# STM32F410Rx register map
File version: 1.0
Registers are 32-bit, read-write, reset 0x0 unless marked. A register's access mark holds for its fields unless they carry their own. Offsets are from the block's base; [hi:lo] are bit positions; {n}, {i} and the like mark numbered series; 'fields as' and 'values as' point back to an identical list.

## RCC — Reset and Clock Control
Base 0x40023800
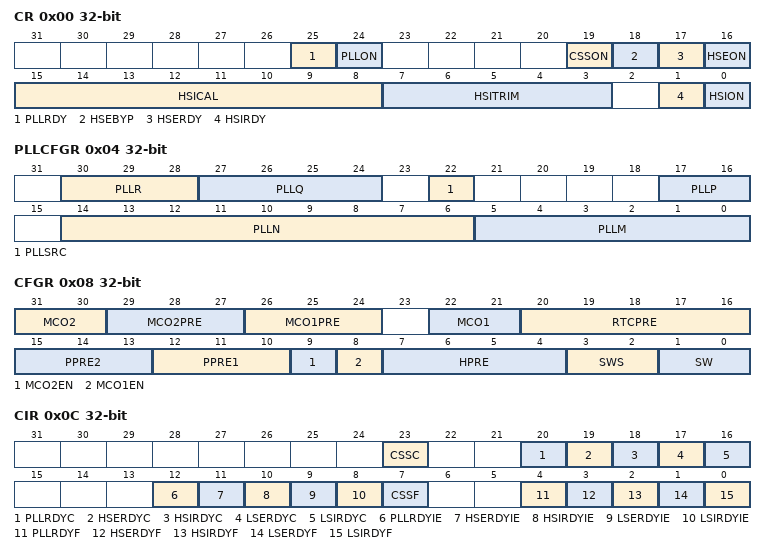
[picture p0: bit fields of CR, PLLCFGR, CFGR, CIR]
0x00 CR — RCC clock control register
  [25] PLLRDY, [24] PLLON, [19] CSSON, [18] HSEBYP, [17] HSERDY, [16] HSEON, [15:8] HSICAL, [7:3] HSITRIM, [1] HSIRDY, [0] HSION
0x04 PLLCFGR — RCC PLL configuration register
  [30:28] PLLR
    {v}=DIV_{v} (Main PLL division factor for PLLCLK (system clock) by {v}) (v=2..7)
  [27:24] PLLQ
    {v}=DIV_{v} (Main PLL division factor for PLLQ output by {v}) (v=2..15)
  [22] PLLSRC
    0=HSI (HSI16 clock selected as PLL entry clock source); 1=HSE (HSE clock selected as PLL entry clock source)
  [17:16] PLLP
    0=DIV_2 (Main PLL division factor for PLLP output by 2); 1=DIV_4 (Main PLL division factor for PLLP output by 4); 2=DIV_6 (Main PLL division factor for PLLP output by 6); 3=DIV_8 (Main PLL division factor for PLLP output by 8)
  [14:6] PLLN
  [5:0] PLLM
    {v}=DIV_{v} (PLL, PLLI2S and PLLSAI division factor by {v}) (v=2..63)
0x08 CFGR — RCC clock configuration register
  [31:30] MCO2
  [29:27] MCO2PRE
  [26:24] MCO1PRE
  [22:21] MCO1
  [20:16] RTCPRE
    0=NOCLOCK (HSE not divided); {v}=HSE_DIV_{v} (HSE clock divided by {v}) (v=2..31)
  [15:13] PPRE2 — PRE2[2:0] bits (APB2 prescaler)
    0=DIV_1 (HCLK not divided); 4=DIV_2 (HCLK divided by 2); 5=DIV_4 (HCLK divided by 4); 6=DIV_8 (HCLK divided by 8); 7=DIV_16 (HCLK divided by 16)
  [12:10] PPRE1 — PRE1[2:0] bits (APB1 prescaler)
    values as PPRE2
  [9] MCO2EN — MCO2EN bit
  [8] MCO1EN — MCO1EN bit
  [7:4] HPRE — HPRE[3:0] bits (AHB prescaler)
    0=DIV_1 (SYSCLK not divided); 8=DIV_2 (SYSCLK divided by 2); 9=DIV_4 (SYSCLK divided by 4); 10=DIV_8 (SYSCLK divided by 8); 11=DIV_16 (SYSCLK divided by 16); 12=DIV_64 (SYSCLK divided by 64); 13=DIV_128 (SYSCLK divided by 128); 14=DIV_256 (SYSCLK divided by 256); 15=DIV_512 (SYSCLK divided by 512)
  [3:2] SWS — SWS[1:0] bits (System Clock Switch Status)
    0=HSI (HSI used as system clock); 1=HSE (HSE used as system clock); 2=PLL (PLL used as system clock)
  [1:0] SW — SW[1:0] bits (System clock Switch)
    0=HSI (HSI selection as system clock); 1=HSE (HSE selection as system clock); 2=PLL (PLL selection as system clock)
0x0C CIR — RCC clock interrupt register
  [23] CSSC, [20] PLLRDYC, [19] HSERDYC, [18] HSIRDYC, [17] LSERDYC, [16] LSIRDYC, [12] PLLRDYIE, [11] HSERDYIE, [10] HSIRDYIE, [9] LSERDYIE, [8] LSIRDYIE, [7] CSSF, [4] PLLRDYF, [3] HSERDYF, [2] HSIRDYF, [1] LSERDYF, [0] LSIRDYF
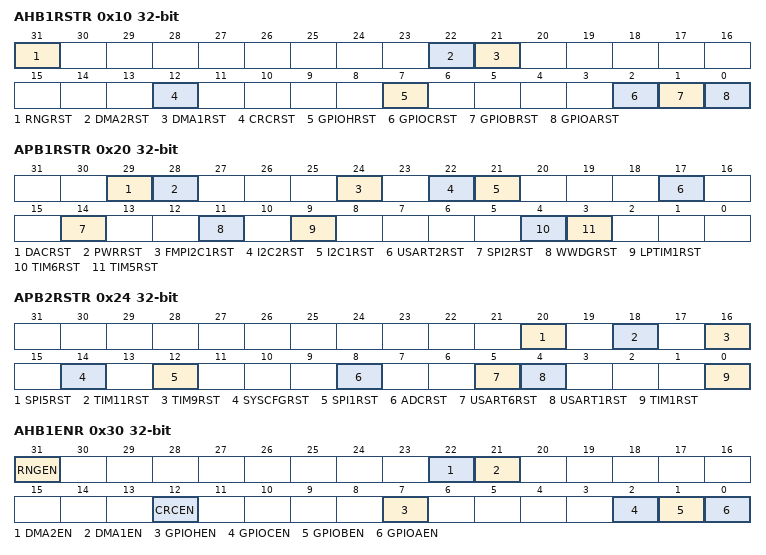
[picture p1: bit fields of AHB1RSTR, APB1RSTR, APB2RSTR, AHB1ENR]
0x10 AHB1RSTR — RCC AHB1 peripheral reset register
  [31] RNGRST, [22] DMA2RST, [21] DMA1RST, [12] CRCRST, [7] GPIOHRST, [2] GPIOCRST, [1] GPIOBRST, [0] GPIOARST
0x20 APB1RSTR — RCC APB1 peripheral reset register
  [29] DACRST, [28] PWRRST, [24] FMPI2C1RST, [22] I2C2RST, [21] I2C1RST, [17] USART2RST, [14] SPI2RST, [11] WWDGRST, [9] LPTIM1RST, [4] TIM6RST, [3] TIM5RST
0x24 APB2RSTR — RCC APB2 peripheral reset register
  [20] SPI5RST, [18] TIM11RST, [16] TIM9RST, [14] SYSCFGRST, [12] SPI1RST, [8] ADCRST, [5] USART6RST, [4] USART1RST, [0] TIM1RST
0x30 AHB1ENR — RCC AHB1 peripheral clock register
  [31] RNGEN, [22] DMA2EN, [21] DMA1EN, [12] CRCEN, [7] GPIOHEN, [2] GPIOCEN, [1] GPIOBEN, [0] GPIOAEN
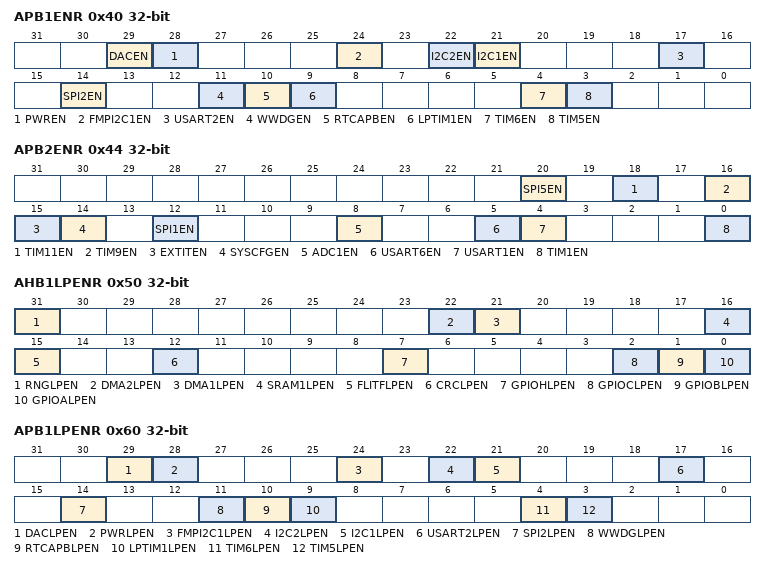
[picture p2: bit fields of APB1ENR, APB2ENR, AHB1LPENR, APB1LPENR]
0x40 APB1ENR — RCC APB1 peripheral clock enable register
  [29] DACEN, [28] PWREN, [24] FMPI2C1EN, [22] I2C2EN, [21] I2C1EN, [17] USART2EN, [14] SPI2EN, [11] WWDGEN, [10] RTCAPBEN, [9] LPTIM1EN, [4] TIM6EN, [3] TIM5EN
0x44 APB2ENR — RCC APB2 peripheral clock enable register
  [20] SPI5EN, [18] TIM11EN, [16] TIM9EN, [15] EXTITEN, [14] SYSCFGEN, [12] SPI1EN, [8] ADC1EN, [5] USART6EN, [4] USART1EN, [0] TIM1EN
0x50 AHB1LPENR — RCC AHB1 peripheral clock enable in low power mode register
  [31] RNGLPEN, [22] DMA2LPEN, [21] DMA1LPEN, [16] SRAM1LPEN, [15] FLITFLPEN, [12] CRCLPEN, [7] GPIOHLPEN, [2] GPIOCLPEN, [1] GPIOBLPEN, [0] GPIOALPEN
0x60 APB1LPENR — RCC APB1 peripheral clock enable in low power mode register
  [29] DACLPEN, [28] PWRLPEN, [24] FMPI2C1LPEN, [22] I2C2LPEN, [21] I2C1LPEN, [17] USART2LPEN, [14] SPI2LPEN, [11] WWDGLPEN, [10] RTCAPBLPEN, [9] LPTIM1LPEN, [4] TIM6LPEN, [3] TIM5LPEN
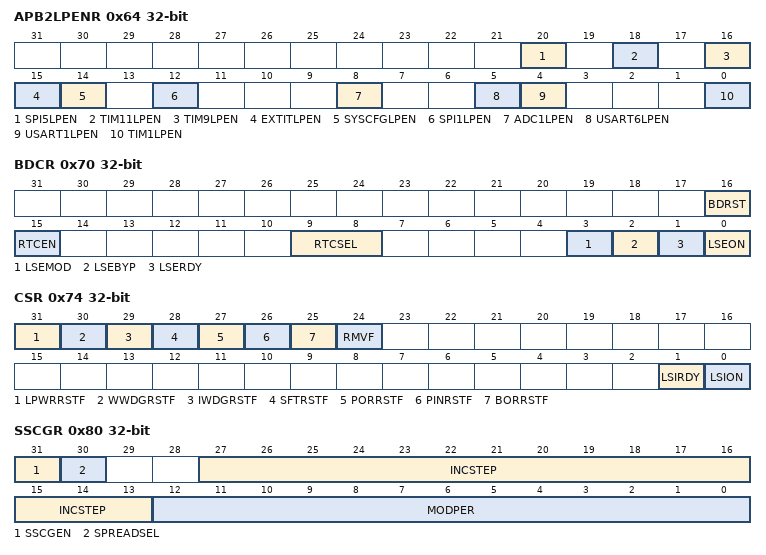
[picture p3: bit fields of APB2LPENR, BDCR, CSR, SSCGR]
0x64 APB2LPENR — RCC APB2 peripheral clock enable in low power mode register
  [20] SPI5LPEN, [18] TIM11LPEN, [16] TIM9LPEN, [15] EXTITLPEN, [14] SYSCFGLPEN, [12] SPI1LPEN, [8] ADC1LPEN, [5] USART6LPEN, [4] USART1LPEN, [0] TIM1LPEN
0x70 BDCR — RCC Backup domain control register
  [16] BDRST
  [15] RTCEN
  [9:8] RTCSEL
    0=NONE (No clock used as RTC clock); 1=LSE (LSE oscillator clock used as RTC clock); 2=LSI (LSI oscillator clock used as RTC clock); 3=HSE (HSE oscillator clock divided by HSE prescaler used as RTC clock)
  [3] LSEMOD
  [2] LSEBYP
  [1] LSERDY
  [0] LSEON
0x74 CSR — RCC clock control & status register
  [31] LPWRRSTF, [30] WWDGRSTF, [29] IWDGRSTF, [28] SFTRSTF, [27] PORRSTF, [26] PINRSTF, [25] BORRSTF, [24] RMVF, [1] LSIRDY, [0] LSION
0x80 SSCGR — RCC spread spectrum clock generation register
  [31] SSCGEN
  [30] SPREADSEL
    0=CENTER (PLL center spread spectrum selection); 1=DOWN (PLL down spread spectrum selection)
  [27:13] INCSTEP
  [12:0] MODPER
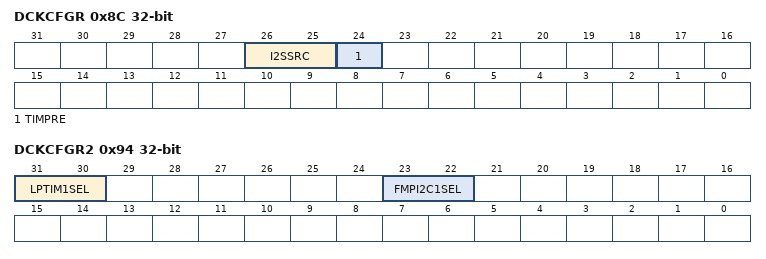
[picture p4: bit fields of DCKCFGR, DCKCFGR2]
0x8C DCKCFGR — RCC DCKCFGR configuration register
  [26:25] I2SSRC
  [24] TIMPRE
    0=TWICE (Timers clock to twice PCLK); 1=FOUR_TIMES (Timers clock to four time PCLK)
0x90 CKGATENR — RCC Clocks Gated ENable Register
0x94 DCKCFGR2 — RCC Dedicated Clocks configuration register 2
  [31:30] LPTIM1SEL
    0=PCLK1 (PCLK1 clock used as LPTIM1 clock); 1=HSI (LSI oscillator clock used as LPTIM1 clock); 2=LSI (HSI oscillator clock used as LPTIM1 clock); 3=LSE (LSE oscillator clock used as LPTIM1 clock)
  [23:22] FMPI2C1SEL
    0=PCLK1 (PCLK1 clock used as FMPI2C1 clock source); 1=SYSCLK (SYSCLK clock used as FMPI2C1 clock source); 2=HSI (HSI clock used as FMPI2C1 clock source)
